AUTOSAR XML (schema 4-2-2)
package /STELLANTIS/EPT/ASWCs
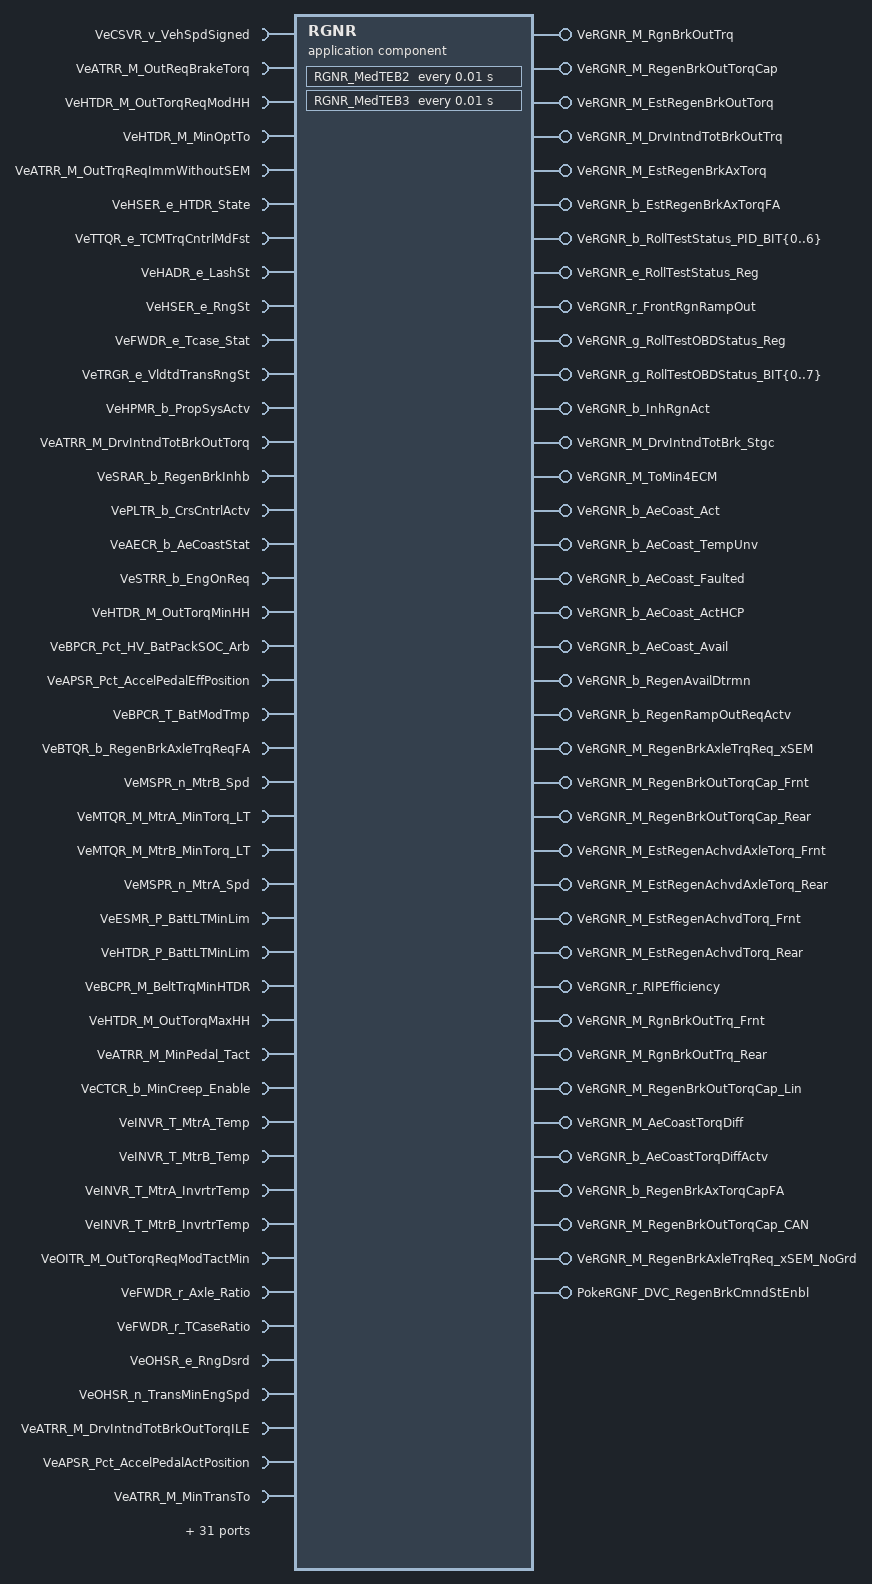
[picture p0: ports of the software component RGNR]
  application sw component type RGNR
    73 x require port:
      VeCSVR_v_VehSpdSigned: nonqueued-receiver-com-spec{data-element=Value, init-value=0}, required-interface=VeCSVR_v_VehSpdSigned
      VeATRR_M_OutReqBrakeTorq: nonqueued-receiver-com-spec{data-element=Value, init-value=0}, required-interface=VeATRR_M_OutReqBrakeTorq
      VeHTDR_M_OutTorqReqModHH: nonqueued-receiver-com-spec{data-element=Value, init-value=0}, required-interface=VeHTDR_M_OutTorqReqModHH
      VeHTDR_M_MinOptTo: nonqueued-receiver-com-spec{data-element=Value, init-value=0}, required-interface=VeHTDR_M_MinOptTo
      VeATRR_M_OutTrqReqImmWithoutSEM: nonqueued-receiver-com-spec{data-element=Value, init-value=0}, required-interface=VeATRR_M_OutTrqReqImmWithoutSEM
      VeHSER_e_HTDR_State: nonqueued-receiver-com-spec{data-element=Value, init-value=CeHSER_e_Neut_State}, required-interface=VeHSER_e_HTDR_State
      VeTTQR_e_TCMTrqCntrlMdFst: nonqueued-receiver-com-spec{data-element=Value, init-value=CeTINR_e_None}, required-interface=VeTTQR_e_TCMTrqCntrlMdFst
      VeHADR_e_LashSt: nonqueued-receiver-com-spec{data-element=Value, init-value=CeHADR_e_LashStZero}, required-interface=VeHADR_e_LashSt
      VeHSER_e_RngSt: nonqueued-receiver-com-spec{data-element=Value, init-value=CeHSER_e_Init}, required-interface=VeHSER_e_RngSt
      VeFWDR_e_Tcase_Stat: nonqueued-receiver-com-spec{data-element=Value, init-value=CeFWDR_e_ShiftINProg}, required-interface=VeFWDR_e_Tcase_Stat
      VeTRGR_e_VldtdTransRngSt: nonqueued-receiver-com-spec{data-element=Value, init-value=CeTRGR_e_NoSelectionAvailable}, required-interface=VeTRGR_e_VldtdTransRngSt
      VeHPMR_b_PropSysActv: nonqueued-receiver-com-spec{data-element=Value, init-value=0}, required-interface=VeHPMR_b_PropSysActv
      VeATRR_M_DrvIntndTotBrkOutTorq: nonqueued-receiver-com-spec{data-element=Value, init-value=0}, required-interface=VeATRR_M_DrvIntndTotBrkOutTorq
      VeSRAR_b_RegenBrkInhb: nonqueued-receiver-com-spec{data-element=Value, init-value=0}, required-interface=VeSRAR_b_RegenBrkInhb
      VePLTR_b_CrsCntrlActv: nonqueued-receiver-com-spec{data-element=Value, init-value=0}, required-interface=VePLTR_b_CrsCntrlActv
      VeAECR_b_AeCoastStat: nonqueued-receiver-com-spec{data-element=Value, init-value=0}, required-interface=VeAECR_b_AeCoastStat
      VeSTRR_b_EngOnReq: nonqueued-receiver-com-spec{data-element=Value, init-value=0}, required-interface=VeSTRR_b_EngOnReq
      VeHTDR_M_OutTorqMinHH: nonqueued-receiver-com-spec{data-element=Value, init-value=0}, required-interface=VeHTDR_M_OutTorqMinHH
      VeBPCR_Pct_HV_BatPackSOC_Arb: nonqueued-receiver-com-spec{data-element=Value, init-value=0}, required-interface=VeBPCR_Pct_HV_BatPackSOC_Arb
      VeAPSR_Pct_AccelPedalEffPosition: nonqueued-receiver-com-spec{data-element=Value, init-value=0}, required-interface=VeAPSR_Pct_AccelPedalEffPosition
      VeBPCR_T_BatModTmp: nonqueued-receiver-com-spec{data-element=Value, init-value=0}, required-interface=VeBPCR_T_BatModTmp
      VeBTQR_b_RegenBrkAxleTrqReqFA: nonqueued-receiver-com-spec{data-element=Value, init-value=0}, required-interface=VeBTQR_b_RegenBrkAxleTrqReqFA
      VeMSPR_n_MtrB_Spd: nonqueued-receiver-com-spec{data-element=Value, init-value=0}, required-interface=VeMSPR_n_MtrB_Spd
      VeMTQR_M_MtrA_MinTorq_LT: nonqueued-receiver-com-spec{data-element=Value, init-value=0}, required-interface=VeMTQR_M_MtrA_MinTorq_LT
      VeMTQR_M_MtrB_MinTorq_LT: nonqueued-receiver-com-spec{data-element=Value, init-value=0}, required-interface=VeMTQR_M_MtrB_MinTorq_LT
      VeMSPR_n_MtrA_Spd: nonqueued-receiver-com-spec{data-element=Value, init-value=0}, required-interface=VeMSPR_n_MtrA_Spd
      VeESMR_P_BattLTMinLim: nonqueued-receiver-com-spec{data-element=Value, init-value=0}, required-interface=VeESMR_P_BattLTMinLim
      VeHTDR_P_BattLTMinLim: nonqueued-receiver-com-spec{data-element=Value, init-value=0}, required-interface=VeHTDR_P_BattLTMinLim
      VeBCPR_M_BeltTrqMinHTDR: nonqueued-receiver-com-spec{data-element=Value, init-value=0}, required-interface=VeBCPR_M_BeltTrqMinHTDR
      VeHTDR_M_OutTorqMaxHH: nonqueued-receiver-com-spec{data-element=Value, init-value=0}, required-interface=VeHTDR_M_OutTorqMaxHH
      VeATRR_M_MinPedal_Tact: nonqueued-receiver-com-spec{data-element=Value, init-value=0}, required-interface=VeATRR_M_MinPedal_Tact
      VeCTCR_b_MinCreep_Enable: nonqueued-receiver-com-spec{data-element=Value, init-value=0}, required-interface=VeCTCR_b_MinCreep_Enable
      VeINVR_T_MtrA_Temp: nonqueued-receiver-com-spec{data-element=Value, init-value=0}, required-interface=VeINVR_T_MtrA_Temp
      VeINVR_T_MtrB_Temp: nonqueued-receiver-com-spec{data-element=Value, init-value=0}, required-interface=VeINVR_T_MtrB_Temp
      VeINVR_T_MtrA_InvrtrTemp: nonqueued-receiver-com-spec{data-element=Value, init-value=0}, required-interface=VeINVR_T_MtrA_InvrtrTemp
      VeINVR_T_MtrB_InvrtrTemp: nonqueued-receiver-com-spec{data-element=Value, init-value=0}, required-interface=VeINVR_T_MtrB_InvrtrTemp
      VeOITR_M_OutTorqReqModTactMin: nonqueued-receiver-com-spec{data-element=Value, init-value=0}, required-interface=VeOITR_M_OutTorqReqModTactMin
      VeFWDR_r_Axle_Ratio: nonqueued-receiver-com-spec{data-element=Value, init-value=0}, required-interface=VeFWDR_r_Axle_Ratio
      VeFWDR_r_TCaseRatio: nonqueued-receiver-com-spec{data-element=Value, init-value=0}, required-interface=VeFWDR_r_TCaseRatio
      VeOHSR_e_RngDsrd: nonqueued-receiver-com-spec{data-element=Value, init-value=CeOHSR_e_RngSel_N}, required-interface=VeOHSR_e_RngDsrd
      VeOHSR_n_TransMinEngSpd: nonqueued-receiver-com-spec{data-element=Value, init-value=0}, required-interface=VeOHSR_n_TransMinEngSpd
      VeATRR_M_DrvIntndTotBrkOutTorqILE: nonqueued-receiver-com-spec{data-element=Value, init-value=0}, required-interface=VeATRR_M_DrvIntndTotBrkOutTorqILE
      VeAPSR_Pct_AccelPedalActPosition: nonqueued-receiver-com-spec{data-element=Value, init-value=0}, required-interface=VeAPSR_Pct_AccelPedalActPosition
      VeATRR_M_MinTransTo: nonqueued-receiver-com-spec{data-element=Value, init-value=0}, required-interface=VeATRR_M_MinTransTo
      VeHTDR_M_MinOptToFrnt: nonqueued-receiver-com-spec{data-element=Value, init-value=0}, required-interface=VeHTDR_M_MinOptToFrnt
      VeHTDR_M_MinOptToRr: nonqueued-receiver-com-spec{data-element=Value, init-value=0}, required-interface=VeHTDR_M_MinOptToRr
      VeHTDR_M_ToFTgt_AWD: nonqueued-receiver-com-spec{data-element=Value, init-value=0}, required-interface=VeHTDR_M_ToFTgt_AWD
      VeHTDR_M_ToRTgt_AWD: nonqueued-receiver-com-spec{data-element=Value, init-value=0}, required-interface=VeHTDR_M_ToRTgt_AWD
      VeHTDR_M_ToFTgt_withRegen: nonqueued-receiver-com-spec{data-element=Value, init-value=0}, required-interface=VeHTDR_M_ToFTgt_withRegen
      VeHTDR_M_ToRTgt_withRegen: nonqueued-receiver-com-spec{data-element=Value, init-value=0}, required-interface=VeHTDR_M_ToRTgt_withRegen
      VeBTQR_M_RegenBrkFrontOffsetReq: nonqueued-receiver-com-spec{data-element=Value, init-value=0}, required-interface=VeBTQR_M_RegenBrkFrontOffsetReq
      VeBTQR_M_RegenBrkRearOffsetReq: nonqueued-receiver-com-spec{data-element=Value, init-value=0}, required-interface=VeBTQR_M_RegenBrkRearOffsetReq
      VeCSVR_n_TransOutSpdSgndFltrd: nonqueued-receiver-com-spec{data-element=Value, init-value=0}, required-interface=VeCSVR_n_TransOutSpdSgndFltrd
      VeTINR_r_TCMTransTrqRatio: nonqueued-receiver-com-spec{data-element=Value, init-value=0}, required-interface=VeTINR_r_TCMTransTrqRatio
      VeTRNR_e_ActualGear: nonqueued-receiver-com-spec{data-element=Value, init-value=CeTRNR_e_Neutral}, required-interface=VeTRNR_e_ActualGear
      VeHTDR_M_ToFTgt_postRegen: nonqueued-receiver-com-spec{data-element=Value, init-value=0}, required-interface=VeHTDR_M_ToFTgt_postRegen
      VeHTDR_M_ToRTgt_postRegen: nonqueued-receiver-com-spec{data-element=Value, init-value=0}, required-interface=VeHTDR_M_ToRTgt_postRegen
      VeATRR_r_Brk2Wheel: nonqueued-receiver-com-spec{data-element=Value, init-value=0}, required-interface=VeATRR_r_Brk2Wheel
      VeBTQR_r_TrqDmnConvSumToAxl: nonqueued-receiver-com-spec{data-element=Value, init-value=0}, required-interface=VeBTQR_r_TrqDmnConvSumToAxl
      VeWTAR_M_AeCoastTorqDiff: nonqueued-receiver-com-spec{data-element=Value, init-value=0}, required-interface=VeWTAR_M_AeCoastTorqDiff
      VeWTAR_b_AeCoastTorqDiffActv: nonqueued-receiver-com-spec{data-element=Value, init-value=0}, required-interface=VeWTAR_b_AeCoastTorqDiffActv
      VeHTDR_M_OptToFront_OptTaTb: nonqueued-receiver-com-spec{data-element=Value, init-value=0}, required-interface=VeHTDR_M_OptToFront_OptTaTb
      VeHTDR_M_OptToRear_OptTaTb: nonqueued-receiver-com-spec{data-element=Value, init-value=0}, required-interface=VeHTDR_M_OptToRear_OptTaTb
      VePDTR_b_EburnEnbl: nonqueued-receiver-com-spec{data-element=Value, init-value=0}, required-interface=VePDTR_b_EburnEnbl
      VeBPCR_T_HV_BatModTempAvg: nonqueued-receiver-com-spec{data-element=Value, init-value=0}, required-interface=VeBPCR_T_HV_BatModTempAvg
      VeINVR_e_MtrA_InvrtrSt: nonqueued-receiver-com-spec{data-element=Value, init-value=CeINVR_e_NormalPowerStageOff}, required-interface=VeINVR_e_MtrA_InvrtrSt
      VeINVR_e_MtrB_InvrtrSt: nonqueued-receiver-com-spec{data-element=Value, init-value=CeINVR_e_NormalPowerStageOff}, required-interface=VeINVR_e_MtrB_InvrtrSt
      VeTIMR_e_RaceOptions_Sts: nonqueued-receiver-com-spec{data-element=Value, init-value=CeTIMR_e_NoOptionSelected}, required-interface=VeTIMR_e_RaceOptions_Sts
      VeTIMR_e_RaceModeSts: nonqueued-receiver-com-spec{data-element=Value, init-value=CeTIMR_e_RaceMode_Off}, required-interface=VeTIMR_e_RaceModeSts
      VeHVTR_I_HV_BattCurrent: nonqueued-receiver-com-spec{data-element=Value, init-value=0}, required-interface=VeHVTR_I_HV_BattCurrent
      VeCCTR_b_CcEngaged: nonqueued-receiver-com-spec{data-element=Value, init-value=0}, required-interface=VeCCTR_b_CcEngaged
      VePLTR_e_ACCSystemSts: nonqueued-receiver-com-spec{data-element=Value, init-value=CePLTR_e_Off}, required-interface=VePLTR_e_ACCSystemSts
      VeSRAR_b_BSMLoCBusOff_CANC_C2: nonqueued-receiver-com-spec{data-element=Value, init-value=0}, required-interface=VeSRAR_b_BSMLoCBusOff_CANC_C2
    51 x provide port:
      VeRGNR_M_RgnBrkOutTrq: nonqueued-sender-com-spec{data-element=Value, init-value=0}, provided-interface=VeRGNR_M_RgnBrkOutTrq
      VeRGNR_M_RegenBrkOutTorqCap: nonqueued-sender-com-spec{data-element=Value, init-value=0}, provided-interface=VeRGNR_M_RegenBrkOutTorqCap
      VeRGNR_M_EstRegenBrkOutTorq: nonqueued-sender-com-spec{data-element=Value, init-value=0}, provided-interface=VeRGNR_M_EstRegenBrkOutTorq
      VeRGNR_M_DrvIntndTotBrkOutTrq: nonqueued-sender-com-spec{data-element=Value, init-value=0}, provided-interface=VeRGNR_M_DrvIntndTotBrkOutTrq
      VeRGNR_M_EstRegenBrkAxTorq: nonqueued-sender-com-spec{data-element=Value, init-value=0}, provided-interface=VeRGNR_M_EstRegenBrkAxTorq
      VeRGNR_b_EstRegenBrkAxTorqFA: nonqueued-sender-com-spec{data-element=Value, init-value=0}, provided-interface=VeRGNR_b_EstRegenBrkAxTorqFA
      VeRGNR_b_RollTestStatus_PID_BIT{0..6}: nonqueued-sender-com-spec{data-element=Value, init-value=0}, provided-interface=VeRGNR_b_RollTestStatus_PID_BIT{0..6}
      VeRGNR_e_RollTestStatus_Reg: nonqueued-sender-com-spec{data-element=Value, init-value=0}, provided-interface=VeRGNR_e_RollTestStatus_Reg
      VeRGNR_r_FrontRgnRampOut: nonqueued-sender-com-spec{data-element=Value, init-value=0}, provided-interface=VeRGNR_r_FrontRgnRampOut
      VeRGNR_g_RollTestOBDStatus_Reg: nonqueued-sender-com-spec{data-element=Value, init-value=0}, provided-interface=VeRGNR_g_RollTestOBDStatus_Reg
      VeRGNR_g_RollTestOBDStatus_BIT{0..7}: nonqueued-sender-com-spec{data-element=Value, init-value=0}, provided-interface=VeRGNR_g_RollTestOBDStatus_BIT{0..7}
      VeRGNR_b_InhRgnAct: nonqueued-sender-com-spec{data-element=Value, init-value=0}, provided-interface=VeRGNR_b_InhRgnAct
      VeRGNR_M_DrvIntndTotBrk_Stgc: nonqueued-sender-com-spec{data-element=Value, init-value=0}, provided-interface=VeRGNR_M_DrvIntndTotBrk_Stgc
      VeRGNR_M_ToMin4ECM: nonqueued-sender-com-spec{data-element=Value, init-value=0}, provided-interface=VeRGNR_M_ToMin4ECM
      VeRGNR_b_AeCoast_Act: nonqueued-sender-com-spec{data-element=Value, init-value=0}, provided-interface=VeRGNR_b_AeCoast_Act
      VeRGNR_b_AeCoast_TempUnv: nonqueued-sender-com-spec{data-element=Value, init-value=0}, provided-interface=VeRGNR_b_AeCoast_TempUnv
      VeRGNR_b_AeCoast_Faulted: nonqueued-sender-com-spec{data-element=Value, init-value=0}, provided-interface=VeRGNR_b_AeCoast_Faulted
      VeRGNR_b_AeCoast_ActHCP: nonqueued-sender-com-spec{data-element=Value, init-value=0}, provided-interface=VeRGNR_b_AeCoast_ActHCP
      VeRGNR_b_AeCoast_Avail: nonqueued-sender-com-spec{data-element=Value, init-value=0}, provided-interface=VeRGNR_b_AeCoast_Avail
      VeRGNR_b_RegenAvailDtrmn: nonqueued-sender-com-spec{data-element=Value, init-value=0}, provided-interface=VeRGNR_b_RegenAvailDtrmn
      VeRGNR_b_RegenRampOutReqActv: nonqueued-sender-com-spec{data-element=Value, init-value=0}, provided-interface=VeRGNR_b_RegenRampOutReqActv
      VeRGNR_M_RegenBrkAxleTrqReq_xSEM: nonqueued-sender-com-spec{data-element=Value, init-value=0}, provided-interface=VeRGNR_M_RegenBrkAxleTrqReq_xSEM
      VeRGNR_M_RegenBrkOutTorqCap_Frnt: nonqueued-sender-com-spec{data-element=Value, init-value=0}, provided-interface=VeRGNR_M_RegenBrkOutTorqCap_Frnt
      VeRGNR_M_RegenBrkOutTorqCap_Rear: nonqueued-sender-com-spec{data-element=Value, init-value=0}, provided-interface=VeRGNR_M_RegenBrkOutTorqCap_Rear
      VeRGNR_M_EstRegenAchvdAxleTorq_Frnt: nonqueued-sender-com-spec{data-element=Value, init-value=0}, provided-interface=VeRGNR_M_EstRegenAchvdAxleTorq_Frnt
      VeRGNR_M_EstRegenAchvdAxleTorq_Rear: nonqueued-sender-com-spec{data-element=Value, init-value=0}, provided-interface=VeRGNR_M_EstRegenAchvdAxleTorq_Rear
      VeRGNR_M_EstRegenAchvdTorq_Frnt: nonqueued-sender-com-spec{data-element=Value, init-value=0}, provided-interface=VeRGNR_M_EstRegenAchvdTorq_Frnt
      VeRGNR_M_EstRegenAchvdTorq_Rear: nonqueued-sender-com-spec{data-element=Value, init-value=0}, provided-interface=VeRGNR_M_EstRegenAchvdTorq_Rear
      VeRGNR_r_RIPEfficiency: nonqueued-sender-com-spec{data-element=Value, init-value=0}, provided-interface=VeRGNR_r_RIPEfficiency
      VeRGNR_M_RgnBrkOutTrq_Frnt: nonqueued-sender-com-spec{data-element=Value, init-value=0}, provided-interface=VeRGNR_M_RgnBrkOutTrq_Frnt
      VeRGNR_M_RgnBrkOutTrq_Rear: nonqueued-sender-com-spec{data-element=Value, init-value=0}, provided-interface=VeRGNR_M_RgnBrkOutTrq_Rear
      VeRGNR_M_RegenBrkOutTorqCap_Lin: nonqueued-sender-com-spec{data-element=Value, init-value=0}, provided-interface=VeRGNR_M_RegenBrkOutTorqCap_Lin
      VeRGNR_M_AeCoastTorqDiff: nonqueued-sender-com-spec{data-element=Value, init-value=0}, provided-interface=VeRGNR_M_AeCoastTorqDiff
      VeRGNR_b_AeCoastTorqDiffActv: nonqueued-sender-com-spec{data-element=Value, init-value=0}, provided-interface=VeRGNR_b_AeCoastTorqDiffActv
      VeRGNR_b_RegenBrkAxTorqCapFA: nonqueued-sender-com-spec{data-element=Value, init-value=0}, provided-interface=VeRGNR_b_RegenBrkAxTorqCapFA
      VeRGNR_M_RegenBrkOutTorqCap_CAN: nonqueued-sender-com-spec{data-element=Value, init-value=0}, provided-interface=VeRGNR_M_RegenBrkOutTorqCap_CAN
      VeRGNR_M_RegenBrkAxleTrqReq_xSEM_NoGrd: nonqueued-sender-com-spec{data-element=Value, init-value=0}, provided-interface=VeRGNR_M_RegenBrkAxleTrqReq_xSEM_NoGrd
      PokeRGNF_DVC_RegenBrkCmndStEnbl: server-com-spec{operation=PokeRGNF_DVC_RegenBrkCmndStEnbl, queue-length=1}, provided-interface=PokeRGNF_DVC_RegenBrkCmndStEnbl
    require port KeHSCR_b_DrvrTrqReqAlwaysWithinLimits: parameter-require-com-spec{init-value=KeHSCR_b_DrvrTrqReqAlwaysWithinLimits_KeHSCR_b_DrvrTrqReqAlwaysWithinLimits:1, parameter=KeHSCR_b_DrvrTrqReqAlwaysWithinLimits}, required-interface=KeHSCR_b_DrvrTrqReqAlwaysWithinLimits
    require port KeHSCR_b_DrvrTrqReqNotLimited: parameter-require-com-spec{init-value=KeHSCR_b_DrvrTrqReqNotLimited_KeHSCR_b_DrvrTrqReqNotLimited:0, parameter=KeHSCR_b_DrvrTrqReqNotLimited}, required-interface=KeHSCR_b_DrvrTrqReqNotLimited
    behavior IB_RGNR: data-type-mapping=msADTtoIDTMapping, handle-termination-and-restart=NO-SUPPORT
      timing event Event_MedTEB2: start-on-event=RGNR_MedTEB2, period=0.01
      timing event Event_MedTEB3: start-on-event=RGNR_MedTEB3, period=0.01
      operation invoked event Event_PokeRGNF_DVC_RegenBrkCmndStEnbl: start-on-event=PokeRGNF_DVC_RegenBrkCmndStEnbl, operation=PokeRGNF_DVC_RegenBrkCmndStEnbl.PokeRGNF_DVC_RegenBrkCmndStEnbl
      init event Event_RGNR_ac_Init: start-on-event=RGNR_ac_Init
      init event Event_PUP: start-on-event=RGNR_PUP
      init event Event_PwrOn: start-on-event=RGNR_PwrOn
      explicit-inter-runnable-variables:
        10 x data, all with category=VALUE, sw-calibration-access=READ-ONLY:
          VeRGNC_M_RegenBrkOutTorqCap_write_IRV: type=Float, init-value=0
          VeRGNC_r_RegenCapFact_write_IRV: type=Float, init-value=0
          VeRGNR_M_RegenBrkOutTorqCap_Frnt_Sign_write_IRV: type=Float, init-value=0
          VeRGNR_M_RegenBrkOutTorqCap_Rear_Sign_write_IRV: type=Float, init-value=0
          VeRGNC_b_InhRgnAct_write_IRV: type=Boolean, init-value=0
          VeRGNC_M_RgnReqAftrDecelLimit_write_IRV: type=Float, init-value=0
          VeRGNC_M_RgnReq_xSEM_write_IRV: type=Float, init-value=0
          VeRGNR_e_RegenBrkCmndStEnbl_write_IRV: type=TeODCR_e_IO_CntrlSt, init-value=CeODCR_e_Return_ECU_Cntrl
          VeRGNR_b_RegenBrkCmndSt_write_IRV: type=Boolean, init-value=0
          VeRGNC_M_TrqRegenBrakingBeforeInhibit_write_IRV: type=Float, init-value=0
      6 x runnable:
        RGNR_ac_Init
        RGNR_PUP
          data-send-points:
            13 x access:
              OUT_VeRGNR_M_RgnBrkOutTrq_Value: accessed-variable=VeRGNR_M_RgnBrkOutTrq.Value
              OUT_VeRGNR_M_RegenBrkOutTorqCap_Value: accessed-variable=VeRGNR_M_RegenBrkOutTorqCap.Value
              OUT_VeRGNR_M_DrvIntndTotBrk_Stgc_Value: accessed-variable=VeRGNR_M_DrvIntndTotBrk_Stgc.Value
              OUT_VeRGNR_M_RegenBrkOutTorqCap_Lin_Value: accessed-variable=VeRGNR_M_RegenBrkOutTorqCap_Lin.Value
              OUT_VeRGNR_M_RegenBrkOutTorqCap_CAN_Value: accessed-variable=VeRGNR_M_RegenBrkOutTorqCap_CAN.Value
              OUT_VeRGNR_M_RegenBrkOutTorqCap_Frnt_Value: accessed-variable=VeRGNR_M_RegenBrkOutTorqCap_Frnt.Value
              OUT_VeRGNR_M_RegenBrkOutTorqCap_Rear_Value: accessed-variable=VeRGNR_M_RegenBrkOutTorqCap_Rear.Value
              OUT_VeRGNR_M_EstRegenBrkOutTorq_Value: accessed-variable=VeRGNR_M_EstRegenBrkOutTorq.Value
              OUT_VeRGNR_M_RgnBrkOutTrq_Frnt_Value: accessed-variable=VeRGNR_M_RgnBrkOutTrq_Frnt.Value
              OUT_VeRGNR_M_RgnBrkOutTrq_Rear_Value: accessed-variable=VeRGNR_M_RgnBrkOutTrq_Rear.Value
              OUT_VeRGNR_M_EstRegenBrkAxTorq_Value: accessed-variable=VeRGNR_M_EstRegenBrkAxTorq.Value
              OUT_VeRGNR_b_EstRegenBrkAxTorqFA_Value: accessed-variable=VeRGNR_b_EstRegenBrkAxTorqFA.Value
              OUT_VeRGNR_M_DrvIntndTotBrkOutTrq_Value: accessed-variable=VeRGNR_M_DrvIntndTotBrkOutTrq.Value
          written-local-variables:
            7 x access:
              WV_VeRGNR_M_RegenBrkOutTorqCap_Frnt_Sign_write_IRV: accessed-variable=VeRGNR_M_RegenBrkOutTorqCap_Frnt_Sign_write_IRV
              WV_VeRGNC_M_RegenBrkOutTorqCap_write_IRV: accessed-variable=VeRGNC_M_RegenBrkOutTorqCap_write_IRV
              WV_VeRGNC_r_RegenCapFact_write_IRV: accessed-variable=VeRGNC_r_RegenCapFact_write_IRV
              WV_VeRGNC_M_RgnReqAftrDecelLimit_write_IRV: accessed-variable=VeRGNC_M_RgnReqAftrDecelLimit_write_IRV
              WV_VeRGNR_M_RegenBrkOutTorqCap_Rear_Sign_write_IRV: accessed-variable=VeRGNR_M_RegenBrkOutTorqCap_Rear_Sign_write_IRV
              WV_VeRGNR_e_RegenBrkCmndStEnbl_write_IRV: accessed-variable=VeRGNR_e_RegenBrkCmndStEnbl_write_IRV
              WV_VeRGNR_b_RegenBrkCmndSt_write_IRV: accessed-variable=VeRGNR_b_RegenBrkCmndSt_write_IRV
        RGNR_MedTEB2
          data-receive-point-by-arguments:
            26 x access:
              IN_VeAECR_b_AeCoastStat_Value: accessed-variable=VeAECR_b_AeCoastStat.Value
              IN_VeAPSR_Pct_AccelPedalActPosition_Value: accessed-variable=VeAPSR_Pct_AccelPedalActPosition.Value
              IN_VeAPSR_Pct_AccelPedalEffPosition_Value: accessed-variable=VeAPSR_Pct_AccelPedalEffPosition.Value
              IN_VeATRR_M_DrvIntndTotBrkOutTorq_Value: accessed-variable=VeATRR_M_DrvIntndTotBrkOutTorq.Value
              IN_VeATRR_M_DrvIntndTotBrkOutTorqILE_Value: accessed-variable=VeATRR_M_DrvIntndTotBrkOutTorqILE.Value
              IN_VeATRR_M_MinPedal_Tact_Value: accessed-variable=VeATRR_M_MinPedal_Tact.Value
              IN_VeATRR_M_OutReqBrakeTorq_Value: accessed-variable=VeATRR_M_OutReqBrakeTorq.Value
              IN_VeATRR_M_OutTrqReqImmWithoutSEM_Value: accessed-variable=VeATRR_M_OutTrqReqImmWithoutSEM.Value
              IN_VeBCPR_M_BeltTrqMinHTDR_Value: accessed-variable=VeBCPR_M_BeltTrqMinHTDR.Value
              IN_VeBTQR_M_RegenBrkFrontOffsetReq_Value: accessed-variable=VeBTQR_M_RegenBrkFrontOffsetReq.Value
              IN_VeBTQR_M_RegenBrkRearOffsetReq_Value: accessed-variable=VeBTQR_M_RegenBrkRearOffsetReq.Value
              IN_VeESMR_P_BattLTMinLim_Value: accessed-variable=VeESMR_P_BattLTMinLim.Value
              IN_VeFWDR_e_Tcase_Stat_Value: accessed-variable=VeFWDR_e_Tcase_Stat.Value
              IN_VeFWDR_r_Axle_Ratio_Value: accessed-variable=VeFWDR_r_Axle_Ratio.Value
              IN_VeFWDR_r_TCaseRatio_Value: accessed-variable=VeFWDR_r_TCaseRatio.Value
              IN_VeHSER_e_RngSt_Value: accessed-variable=VeHSER_e_RngSt.Value
              IN_VeHTDR_M_OutTorqMaxHH_Value: accessed-variable=VeHTDR_M_OutTorqMaxHH.Value
              IN_VeHTDR_P_BattLTMinLim_Value: accessed-variable=VeHTDR_P_BattLTMinLim.Value
              IN_VeHVTR_I_HV_BattCurrent_Value: accessed-variable=VeHVTR_I_HV_BattCurrent.Value
              IN_VeMSPR_n_MtrA_Spd_Value: accessed-variable=VeMSPR_n_MtrA_Spd.Value
              IN_VeMSPR_n_MtrB_Spd_Value: accessed-variable=VeMSPR_n_MtrB_Spd.Value
              IN_VeMTQR_M_MtrA_MinTorq_LT_Value: accessed-variable=VeMTQR_M_MtrA_MinTorq_LT.Value
              IN_VeMTQR_M_MtrB_MinTorq_LT_Value: accessed-variable=VeMTQR_M_MtrB_MinTorq_LT.Value
              IN_VeOHSR_e_RngDsrd_Value: accessed-variable=VeOHSR_e_RngDsrd.Value
              IN_VeOHSR_n_TransMinEngSpd_Value: accessed-variable=VeOHSR_n_TransMinEngSpd.Value
              IN_VeTRGR_e_VldtdTransRngSt_Value: accessed-variable=VeTRGR_e_VldtdTransRngSt.Value
          data-send-points:
            25 x access:
              OUT_VeRGNR_M_RgnBrkOutTrq_Value: accessed-variable=VeRGNR_M_RgnBrkOutTrq.Value
              OUT_VeRGNR_M_DrvIntndTotBrk_Stgc_Value: accessed-variable=VeRGNR_M_DrvIntndTotBrk_Stgc.Value
              OUT_VeRGNR_M_RgnBrkOutTrq_Frnt_Value: accessed-variable=VeRGNR_M_RgnBrkOutTrq_Frnt.Value
              OUT_VeRGNR_M_RgnBrkOutTrq_Rear_Value: accessed-variable=VeRGNR_M_RgnBrkOutTrq_Rear.Value
              OUT_VeRGNR_M_DrvIntndTotBrkOutTrq_Value: accessed-variable=VeRGNR_M_DrvIntndTotBrkOutTrq.Value
              OUT_VeRGNR_b_RegenRampOutReqActv_Value: accessed-variable=VeRGNR_b_RegenRampOutReqActv.Value
              OUT_VeRGNR_M_RegenBrkAxleTrqReq_xSEM_Value: accessed-variable=VeRGNR_M_RegenBrkAxleTrqReq_xSEM.Value
              OUT_VeRGNR_b_RollTestStatus_PID_BIT{0..6}_Value: accessed-variable=VeRGNR_b_RollTestStatus_PID_BIT{0..6}.Value
              OUT_VeRGNR_e_RollTestStatus_Reg_Value: accessed-variable=VeRGNR_e_RollTestStatus_Reg.Value
              OUT_VeRGNR_g_RollTestOBDStatus_Reg_Value: accessed-variable=VeRGNR_g_RollTestOBDStatus_Reg.Value
              OUT_VeRGNR_g_RollTestOBDStatus_BIT{0..7}_Value: accessed-variable=VeRGNR_g_RollTestOBDStatus_BIT{0..7}.Value
              OUT_VeRGNR_M_RegenBrkAxleTrqReq_xSEM_NoGrd_Value: accessed-variable=VeRGNR_M_RegenBrkAxleTrqReq_xSEM_NoGrd.Value
          read-local-variables:
            6 x access:
              RV_VeRGNC_M_RegenBrkOutTorqCap_write_IRV: accessed-variable=VeRGNC_M_RegenBrkOutTorqCap_write_IRV
              RV_VeRGNC_M_RgnReqAftrDecelLimit_write_IRV: accessed-variable=VeRGNC_M_RgnReqAftrDecelLimit_write_IRV
              RV_VeRGNC_b_InhRgnAct_write_IRV: accessed-variable=VeRGNC_b_InhRgnAct_write_IRV
              RV_VeRGNC_r_RegenCapFact_write_IRV: accessed-variable=VeRGNC_r_RegenCapFact_write_IRV
              RV_VeRGNR_M_RegenBrkOutTorqCap_Frnt_Sign_write_IRV: accessed-variable=VeRGNR_M_RegenBrkOutTorqCap_Frnt_Sign_write_IRV
              RV_VeRGNR_M_RegenBrkOutTorqCap_Rear_Sign_write_IRV: accessed-variable=VeRGNR_M_RegenBrkOutTorqCap_Rear_Sign_write_IRV
          written-local-variables:
            access WV_VeRGNC_M_RgnReqAftrDecelLimit_write_IRV: accessed-variable=VeRGNC_M_RgnReqAftrDecelLimit_write_IRV
            access WV_VeRGNC_M_RgnReq_xSEM_write_IRV: accessed-variable=VeRGNC_M_RgnReq_xSEM_write_IRV
            access WV_VeRGNC_M_TrqRegenBrakingBeforeInhibit_write_IRV: accessed-variable=VeRGNC_M_TrqRegenBrakingBeforeInhibit_write_IRV
        RGNR_MedTEB3
          data-receive-point-by-arguments:
            55 x access:
              IN_VeAECR_b_AeCoastStat_Value: accessed-variable=VeAECR_b_AeCoastStat.Value
              IN_VeAPSR_Pct_AccelPedalEffPosition_Value: accessed-variable=VeAPSR_Pct_AccelPedalEffPosition.Value
              IN_VeATRR_M_DrvIntndTotBrkOutTorq_Value: accessed-variable=VeATRR_M_DrvIntndTotBrkOutTorq.Value
              IN_VeATRR_M_MinPedal_Tact_Value: accessed-variable=VeATRR_M_MinPedal_Tact.Value
              IN_VeATRR_M_MinTransTo_Value: accessed-variable=VeATRR_M_MinTransTo.Value
              IN_VeATRR_M_OutTrqReqImmWithoutSEM_Value: accessed-variable=VeATRR_M_OutTrqReqImmWithoutSEM.Value
              IN_VeATRR_r_Brk2Wheel_Value: accessed-variable=VeATRR_r_Brk2Wheel.Value
              IN_VeBPCR_Pct_HV_BatPackSOC_Arb_Value: accessed-variable=VeBPCR_Pct_HV_BatPackSOC_Arb.Value
              IN_VeBPCR_T_BatModTmp_Value: accessed-variable=VeBPCR_T_BatModTmp.Value
              IN_VeBPCR_T_HV_BatModTempAvg_Value: accessed-variable=VeBPCR_T_HV_BatModTempAvg.Value
              IN_VeBTQR_b_RegenBrkAxleTrqReqFA_Value: accessed-variable=VeBTQR_b_RegenBrkAxleTrqReqFA.Value
              IN_VeBTQR_r_TrqDmnConvSumToAxl_Value: accessed-variable=VeBTQR_r_TrqDmnConvSumToAxl.Value
              IN_VeCCTR_b_CcEngaged_Value: accessed-variable=VeCCTR_b_CcEngaged.Value
              IN_VeCSVR_n_TransOutSpdSgndFltrd_Value: accessed-variable=VeCSVR_n_TransOutSpdSgndFltrd.Value
              IN_VeCSVR_v_VehSpdSigned_Value: accessed-variable=VeCSVR_v_VehSpdSigned.Value
              IN_VeCTCR_b_MinCreep_Enable_Value: accessed-variable=VeCTCR_b_MinCreep_Enable.Value
              IN_VeFWDR_e_Tcase_Stat_Value: accessed-variable=VeFWDR_e_Tcase_Stat.Value
              IN_VeHADR_e_LashSt_Value: accessed-variable=VeHADR_e_LashSt.Value
              IN_VeHPMR_b_PropSysActv_Value: accessed-variable=VeHPMR_b_PropSysActv.Value
              IN_VeHSER_e_HTDR_State_Value: accessed-variable=VeHSER_e_HTDR_State.Value
              IN_VeHTDR_M_MinOptTo_Value: accessed-variable=VeHTDR_M_MinOptTo.Value
              IN_VeHTDR_M_MinOptToFrnt_Value: accessed-variable=VeHTDR_M_MinOptToFrnt.Value
              IN_VeHTDR_M_MinOptToRr_Value: accessed-variable=VeHTDR_M_MinOptToRr.Value
              IN_VeHTDR_M_OptToFront_OptTaTb_Value: accessed-variable=VeHTDR_M_OptToFront_OptTaTb.Value
              IN_VeHTDR_M_OptToRear_OptTaTb_Value: accessed-variable=VeHTDR_M_OptToRear_OptTaTb.Value
              IN_VeHTDR_M_OutTorqMinHH_Value: accessed-variable=VeHTDR_M_OutTorqMinHH.Value
              IN_VeHTDR_M_OutTorqReqModHH_Value: accessed-variable=VeHTDR_M_OutTorqReqModHH.Value
              IN_VeHTDR_M_ToFTgt_AWD_Value: accessed-variable=VeHTDR_M_ToFTgt_AWD.Value
              IN_VeHTDR_M_ToFTgt_postRegen_Value: accessed-variable=VeHTDR_M_ToFTgt_postRegen.Value
              IN_VeHTDR_M_ToFTgt_withRegen_Value: accessed-variable=VeHTDR_M_ToFTgt_withRegen.Value
              IN_VeHTDR_M_ToRTgt_AWD_Value: accessed-variable=VeHTDR_M_ToRTgt_AWD.Value
              IN_VeHTDR_M_ToRTgt_postRegen_Value: accessed-variable=VeHTDR_M_ToRTgt_postRegen.Value
              IN_VeHTDR_M_ToRTgt_withRegen_Value: accessed-variable=VeHTDR_M_ToRTgt_withRegen.Value
              IN_VeINVR_T_MtrA_InvrtrTemp_Value: accessed-variable=VeINVR_T_MtrA_InvrtrTemp.Value
              IN_VeINVR_T_MtrA_Temp_Value: accessed-variable=VeINVR_T_MtrA_Temp.Value
              IN_VeINVR_T_MtrB_InvrtrTemp_Value: accessed-variable=VeINVR_T_MtrB_InvrtrTemp.Value
              IN_VeINVR_T_MtrB_Temp_Value: accessed-variable=VeINVR_T_MtrB_Temp.Value
              IN_VeINVR_e_MtrA_InvrtrSt_Value: accessed-variable=VeINVR_e_MtrA_InvrtrSt.Value
              IN_VeINVR_e_MtrB_InvrtrSt_Value: accessed-variable=VeINVR_e_MtrB_InvrtrSt.Value
              IN_VeMSPR_n_MtrB_Spd_Value: accessed-variable=VeMSPR_n_MtrB_Spd.Value
              IN_VeOITR_M_OutTorqReqModTactMin_Value: accessed-variable=VeOITR_M_OutTorqReqModTactMin.Value
              IN_VePDTR_b_EburnEnbl_Value: accessed-variable=VePDTR_b_EburnEnbl.Value
              IN_VePLTR_b_CrsCntrlActv_Value: accessed-variable=VePLTR_b_CrsCntrlActv.Value
              IN_VePLTR_e_ACCSystemSts_Value: accessed-variable=VePLTR_e_ACCSystemSts.Value
              IN_VeSRAR_b_BSMLoCBusOff_CANC_C2_Value: accessed-variable=VeSRAR_b_BSMLoCBusOff_CANC_C2.Value
              IN_VeSRAR_b_RegenBrkInhb_Value: accessed-variable=VeSRAR_b_RegenBrkInhb.Value
              IN_VeSTRR_b_EngOnReq_Value: accessed-variable=VeSTRR_b_EngOnReq.Value
              IN_VeTIMR_e_RaceModeSts_Value: accessed-variable=VeTIMR_e_RaceModeSts.Value
              IN_VeTIMR_e_RaceOptions_Sts_Value: accessed-variable=VeTIMR_e_RaceOptions_Sts.Value
              IN_VeTINR_r_TCMTransTrqRatio_Value: accessed-variable=VeTINR_r_TCMTransTrqRatio.Value
              IN_VeTRGR_e_VldtdTransRngSt_Value: accessed-variable=VeTRGR_e_VldtdTransRngSt.Value
              IN_VeTRNR_e_ActualGear_Value: accessed-variable=VeTRNR_e_ActualGear.Value
              IN_VeTTQR_e_TCMTrqCntrlMdFst_Value: accessed-variable=VeTTQR_e_TCMTrqCntrlMdFst.Value
              IN_VeWTAR_M_AeCoastTorqDiff_Value: accessed-variable=VeWTAR_M_AeCoastTorqDiff.Value
              IN_VeWTAR_b_AeCoastTorqDiffActv_Value: accessed-variable=VeWTAR_b_AeCoastTorqDiffActv.Value
          data-send-points:
            25 x access:
              OUT_VeRGNR_b_InhRgnAct_Value: accessed-variable=VeRGNR_b_InhRgnAct.Value
              OUT_VeRGNR_M_RegenBrkOutTorqCap_Value: accessed-variable=VeRGNR_M_RegenBrkOutTorqCap.Value
              OUT_VeRGNR_M_RegenBrkOutTorqCap_Lin_Value: accessed-variable=VeRGNR_M_RegenBrkOutTorqCap_Lin.Value
              OUT_VeRGNR_M_RegenBrkOutTorqCap_CAN_Value: accessed-variable=VeRGNR_M_RegenBrkOutTorqCap_CAN.Value
              OUT_VeRGNR_M_RegenBrkOutTorqCap_Frnt_Value: accessed-variable=VeRGNR_M_RegenBrkOutTorqCap_Frnt.Value
              OUT_VeRGNR_M_RegenBrkOutTorqCap_Rear_Value: accessed-variable=VeRGNR_M_RegenBrkOutTorqCap_Rear.Value
              OUT_VeRGNR_M_EstRegenBrkOutTorq_Value: accessed-variable=VeRGNR_M_EstRegenBrkOutTorq.Value
              OUT_VeRGNR_M_EstRegenBrkAxTorq_Value: accessed-variable=VeRGNR_M_EstRegenBrkAxTorq.Value
              OUT_VeRGNR_b_EstRegenBrkAxTorqFA_Value: accessed-variable=VeRGNR_b_EstRegenBrkAxTorqFA.Value
              OUT_VeRGNR_r_FrontRgnRampOut_Value: accessed-variable=VeRGNR_r_FrontRgnRampOut.Value
              OUT_VeRGNR_M_ToMin4ECM_Value: accessed-variable=VeRGNR_M_ToMin4ECM.Value
              OUT_VeRGNR_b_AeCoast_Act_Value: accessed-variable=VeRGNR_b_AeCoast_Act.Value
              OUT_VeRGNR_b_AeCoast_ActHCP_Value: accessed-variable=VeRGNR_b_AeCoast_ActHCP.Value
              OUT_VeRGNR_b_AeCoast_TempUnv_Value: accessed-variable=VeRGNR_b_AeCoast_TempUnv.Value
              OUT_VeRGNR_b_AeCoast_Faulted_Value: accessed-variable=VeRGNR_b_AeCoast_Faulted.Value
              OUT_VeRGNR_b_AeCoast_Avail_Value: accessed-variable=VeRGNR_b_AeCoast_Avail.Value
              OUT_VeRGNR_b_RegenAvailDtrmn_Value: accessed-variable=VeRGNR_b_RegenAvailDtrmn.Value
              OUT_VeRGNR_M_EstRegenAchvdAxleTorq_Frnt_Value: accessed-variable=VeRGNR_M_EstRegenAchvdAxleTorq_Frnt.Value
              OUT_VeRGNR_M_EstRegenAchvdAxleTorq_Rear_Value: accessed-variable=VeRGNR_M_EstRegenAchvdAxleTorq_Rear.Value
              OUT_VeRGNR_M_EstRegenAchvdTorq_Frnt_Value: accessed-variable=VeRGNR_M_EstRegenAchvdTorq_Frnt.Value
              OUT_VeRGNR_M_EstRegenAchvdTorq_Rear_Value: accessed-variable=VeRGNR_M_EstRegenAchvdTorq_Rear.Value
              OUT_VeRGNR_r_RIPEfficiency_Value: accessed-variable=VeRGNR_r_RIPEfficiency.Value
              OUT_VeRGNR_M_AeCoastTorqDiff_Value: accessed-variable=VeRGNR_M_AeCoastTorqDiff.Value
              OUT_VeRGNR_b_AeCoastTorqDiffActv_Value: accessed-variable=VeRGNR_b_AeCoastTorqDiffActv.Value
              OUT_VeRGNR_b_RegenBrkAxTorqCapFA_Value: accessed-variable=VeRGNR_b_RegenBrkAxTorqCapFA.Value
          parameter access CALPRM_KeHSCR_b_DrvrTrqReqAlwaysWithinLimits_KeHSCR_b_DrvrTrqReqAlwaysWithinLimits: accessed-parameter=KeHSCR_b_DrvrTrqReqAlwaysWithinLimits.KeHSCR_b_DrvrTrqReqAlwaysWithinLimits
          parameter access CALPRM_KeHSCR_b_DrvrTrqReqNotLimited_KeHSCR_b_DrvrTrqReqNotLimited: accessed-parameter=KeHSCR_b_DrvrTrqReqNotLimited.KeHSCR_b_DrvrTrqReqNotLimited
          read-local-variables:
            4 x access:
              RV_VeRGNC_M_RgnReq_xSEM_write_IRV: accessed-variable=VeRGNC_M_RgnReq_xSEM_write_IRV
              RV_VeRGNC_M_TrqRegenBrakingBeforeInhibit_write_IRV: accessed-variable=VeRGNC_M_TrqRegenBrakingBeforeInhibit_write_IRV
              RV_VeRGNR_b_RegenBrkCmndSt_write_IRV: accessed-variable=VeRGNR_b_RegenBrkCmndSt_write_IRV
              RV_VeRGNR_e_RegenBrkCmndStEnbl_write_IRV: accessed-variable=VeRGNR_e_RegenBrkCmndStEnbl_write_IRV
          written-local-variables:
            5 x access:
              WV_VeRGNC_M_RegenBrkOutTorqCap_write_IRV: accessed-variable=VeRGNC_M_RegenBrkOutTorqCap_write_IRV
              WV_VeRGNC_b_InhRgnAct_write_IRV: accessed-variable=VeRGNC_b_InhRgnAct_write_IRV
              WV_VeRGNC_r_RegenCapFact_write_IRV: accessed-variable=VeRGNC_r_RegenCapFact_write_IRV
              WV_VeRGNR_M_RegenBrkOutTorqCap_Frnt_Sign_write_IRV: accessed-variable=VeRGNR_M_RegenBrkOutTorqCap_Frnt_Sign_write_IRV
              WV_VeRGNR_M_RegenBrkOutTorqCap_Rear_Sign_write_IRV: accessed-variable=VeRGNR_M_RegenBrkOutTorqCap_Rear_Sign_write_IRV
        RGNR_PwrOn
          data-send-points:
            37 x access:
              OUT_VeRGNR_b_RollTestStatus_PID_BIT{0..6}_Value: accessed-variable=VeRGNR_b_RollTestStatus_PID_BIT{0..6}.Value
              OUT_VeRGNR_e_RollTestStatus_Reg_Value: accessed-variable=VeRGNR_e_RollTestStatus_Reg.Value
              OUT_VeRGNR_r_FrontRgnRampOut_Value: accessed-variable=VeRGNR_r_FrontRgnRampOut.Value
              OUT_VeRGNR_g_RollTestOBDStatus_Reg_Value: accessed-variable=VeRGNR_g_RollTestOBDStatus_Reg.Value
              OUT_VeRGNR_g_RollTestOBDStatus_BIT{0..7}_Value: accessed-variable=VeRGNR_g_RollTestOBDStatus_BIT{0..7}.Value
              OUT_VeRGNR_b_InhRgnAct_Value: accessed-variable=VeRGNR_b_InhRgnAct.Value
              OUT_VeRGNR_M_ToMin4ECM_Value: accessed-variable=VeRGNR_M_ToMin4ECM.Value
              OUT_VeRGNR_b_AeCoast_Act_Value: accessed-variable=VeRGNR_b_AeCoast_Act.Value
              OUT_VeRGNR_b_AeCoast_TempUnv_Value: accessed-variable=VeRGNR_b_AeCoast_TempUnv.Value
              OUT_VeRGNR_b_AeCoast_Faulted_Value: accessed-variable=VeRGNR_b_AeCoast_Faulted.Value
              OUT_VeRGNR_b_AeCoast_Avail_Value: accessed-variable=VeRGNR_b_AeCoast_Avail.Value
              OUT_VeRGNR_b_AeCoast_ActHCP_Value: accessed-variable=VeRGNR_b_AeCoast_ActHCP.Value
              OUT_VeRGNR_b_RegenAvailDtrmn_Value: accessed-variable=VeRGNR_b_RegenAvailDtrmn.Value
              OUT_VeRGNR_b_RegenRampOutReqActv_Value: accessed-variable=VeRGNR_b_RegenRampOutReqActv.Value
              OUT_VeRGNR_M_RegenBrkAxleTrqReq_xSEM_Value: accessed-variable=VeRGNR_M_RegenBrkAxleTrqReq_xSEM.Value
              OUT_VeRGNR_M_EstRegenAchvdAxleTorq_Frnt_Value: accessed-variable=VeRGNR_M_EstRegenAchvdAxleTorq_Frnt.Value
              OUT_VeRGNR_M_EstRegenAchvdAxleTorq_Rear_Value: accessed-variable=VeRGNR_M_EstRegenAchvdAxleTorq_Rear.Value
              OUT_VeRGNR_M_EstRegenAchvdTorq_Frnt_Value: accessed-variable=VeRGNR_M_EstRegenAchvdTorq_Frnt.Value
              OUT_VeRGNR_M_EstRegenAchvdTorq_Rear_Value: accessed-variable=VeRGNR_M_EstRegenAchvdTorq_Rear.Value
              OUT_VeRGNR_r_RIPEfficiency_Value: accessed-variable=VeRGNR_r_RIPEfficiency.Value
              OUT_VeRGNR_M_AeCoastTorqDiff_Value: accessed-variable=VeRGNR_M_AeCoastTorqDiff.Value
              OUT_VeRGNR_b_AeCoastTorqDiffActv_Value: accessed-variable=VeRGNR_b_AeCoastTorqDiffActv.Value
              OUT_VeRGNR_b_RegenBrkAxTorqCapFA_Value: accessed-variable=VeRGNR_b_RegenBrkAxTorqCapFA.Value
              OUT_VeRGNR_M_RegenBrkAxleTrqReq_xSEM_NoGrd_Value: accessed-variable=VeRGNR_M_RegenBrkAxleTrqReq_xSEM_NoGrd.Value
          written-local-variables:
            access WV_VeRGNC_M_RgnReq_xSEM_write_IRV: accessed-variable=VeRGNC_M_RgnReq_xSEM_write_IRV
            access WV_VeRGNC_M_TrqRegenBrakingBeforeInhibit_write_IRV: accessed-variable=VeRGNC_M_TrqRegenBrakingBeforeInhibit_write_IRV
            access WV_VeRGNC_b_InhRgnAct_write_IRV: accessed-variable=VeRGNC_b_InhRgnAct_write_IRV
        PokeRGNF_DVC_RegenBrkCmndStEnbl
          written-local-variables:
            access WV_VeRGNR_b_RegenBrkCmndSt_write_IRV: accessed-variable=VeRGNR_b_RegenBrkCmndSt_write_IRV
            access WV_VeRGNR_e_RegenBrkCmndStEnbl_write_IRV: accessed-variable=VeRGNR_e_RegenBrkCmndStEnbl_write_IRV
      5 x variation point proxy, all with category=CONDITION:
        Variant_RGNR_{1..4}: condition-access=0
        Variant_RGNR_5: condition-access=1
